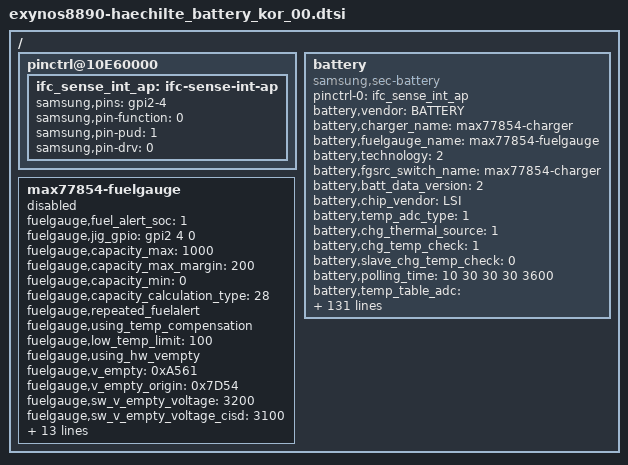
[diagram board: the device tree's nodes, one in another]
/*
 * SAMSUNG UNIVERSAL5433 board device tree source
 *
 * Copyright (c) 2013 Samsung Electronics Co., Ltd.
 *		http://www.samsung.com
 *
 * This program is free software; you can redistribute it and/or modify
 * it under the terms of the GNU General Public License version 2 as
 * published by the Free Software Foundation.
*/

/ {
	pinctrl@10E60000 {

		ifc_sense_int_ap: ifc-sense-int-ap {
			samsung,pins = "gpi2-4";
			samsung,pin-function = <0>;
			samsung,pin-pud = <1>;
			samsung,pin-drv = <0>;
		};
	};
	battery {
		status = "okay";
		compatible = "samsung,sec-battery";

		pinctrl-names = "default";
		pinctrl-0 = <&ifc_sense_int_ap>;
		/* battery,irq_gpio = <&gpa1 6 0>; */

		battery,vendor = "BATTERY";
		battery,charger_name = "max77854-charger";
		battery,fuelgauge_name = "max77854-fuelgauge";
		battery,technology = <2>; /* POWER_SUPPLY_TECHNOLOGY_LION */
		battery,fgsrc_switch_name = "max77854-charger"; /* Fuelgauge voltage source */

		battery,batt_data_version = <2>;

		battery,chip_vendor = "LSI";
		battery,temp_adc_type = <1>; /* SEC_BATTERY_ADC_TYPE_AP */

		battery,chg_thermal_source = <1>;
		battery,chg_temp_check = <1>;
		battery,slave_chg_temp_check = <0>;

		battery,polling_time = <10 30 30 30 3600>;

		battery,temp_table_adc = <325 370 425 572 640 784 910 1058 1235 1407 1600 1835 2282 2767 2970 3160 3322 3464 3688>;
		battery,temp_table_data = <900 850 800 700 650 600 550 500 450 400 350 300 200 100 50 0 (-50) (-100) (-200)>;

		battery,chg_temp_table_adc = <307 351 405 511 647 758 885 1031 1208 1363 1549 1792 2224 2738 2941 3135 3299 3455 3672>;
		battery,chg_temp_table_data = <900 850 800 700 650 600 550 500 450 400 350 300 200 100 50 0 (-50) (-100) (-200)>;

		battery,input_current_limit = <1800 450 450 1800 500 900 1000 460 1000 450 900 900 900 1900 1800 450 450 400 700 1300 300 1000 1500 450 1675 1800 1000 1675 80 1800 1675 1400 1000 1000 600 900 900 900 1675 1800>;
		battery,fast_charging_current = <2100 450 450 2100 800 1200 1000 460 1200 450 2100 2100 2100 1600 2100 450 450 400 700 1300 300 1000 1500 450 2800 2800 1000 2800 80 1800 1000 1400 450 1000 2100 2100 2100 2100 2800 2250>;
		battery,full_check_current_1st = <450 0 0 450 450 450 450 450 450 0 450 450 450 450 450 0 0 450 450 450 450 450 450 0 450 450 450 450 0 450 450 450 0 450 450 450 450 450 450 450>;
		battery,full_check_current_2nd = <250 0 0 250 250 250 250 250 250 0 250 250 250 250 250 0 0 250 250 250 250 250 250 0 250 250 250 250 0 250 250 250 0 250 250 250 250 250 250 250>;

		battery,wireless_cc_cv = <85>;
		battery,inbat_voltage = <1>;
		battery,inbat_voltage_table_adc = <3120 3101 3061 3038 3001 2956 2920 2887 2856 2814
						2793 2754 2720 2677 2641 2613 2572 2531 2502 2467 2436>;
		battery,inbat_voltage_table_data = <438 435 430 425 420 415 410 405 400 395
						390 385 380 375 370 365 360 355 350 345 340>;

		battery,adc_check_count = <5>;

		battery,cable_check_type = <4>; /* SEC_BATTERY_CABLE_CHECK_PSY */
		battery,cable_source_type = <1>; /* SEC_BATTERY_CABLE_SOURCE_EXTERNAL */
		battery,polling_type = <1>; /* SEC_BATTERY_MONITOR_ALARM */
		battery,monitor_initial_count = <0>;

		battery,battery_check_type = <5>; /* SEC_BATTERY_CHECK_CHARGER */
		battery,check_count = <0>;
		battery,check_adc_max = <1440>;
		battery,check_adc_min = <0>;

		battery,ovp_uvlo_check_type = <3>; /* SEC_BATTERY_OVP_UVLO_CHGPOLLING */

		battery,thermal_source = <2>; /* SEC_BATTERY_THERMAL_SOURCE_ADC */

		battery,temp_check_type = <2>; /* SEC_BATTERY_TEMP_CHECK_TEMP */
		battery,temp_check_count = <1>;
		battery,temp_highlimit_threshold_event = <800>;
		battery,temp_highlimit_recovery_event = <750>;
		battery,temp_high_threshold_event = <500>;
		battery,temp_high_recovery_event = <450>;
		battery,temp_low_threshold_event = <0>;
		battery,temp_low_recovery_event = <50>;
		battery,temp_highlimit_threshold_normal = <800>;
		battery,temp_highlimit_recovery_normal = <750>;
		battery,temp_high_threshold_normal = <500>;
		battery,temp_high_recovery_normal = <450>;
		battery,temp_low_threshold_normal = <0>;
		battery,temp_low_recovery_normal = <50>;
		battery,temp_highlimit_threshold_lpm = <800>;
		battery,temp_highlimit_recovery_lpm = <750>;
		battery,temp_high_threshold_lpm = <500>;
		battery,temp_high_recovery_lpm = <450>;
		battery,temp_low_threshold_lpm = <0>;
		battery,temp_low_recovery_lpm = <50>;
		battery,full_check_type = <7>; /* SEC_BATTERY_FULLCHARGED_CHGPSY */
		battery,full_check_type_2nd = <7>; /* SEC_BATTERY_FULLCHARGED_CHGPSY */
		battery,full_check_count = <1>;
		battery,chg_gpio_full_check = <0>;
		battery,chg_polarity_full_check = <1>;

		battery,chg_high_temp_1st = <515>;
		battery,chg_high_temp_2nd = <515>;
		battery,chg_high_temp_recovery = <500>;
		battery,chg_charging_limit_current = <1033>;
		battery,chg_charging_limit_current_2nd = <1033>;

		battery,sleep_mode_limit_current = <500>;
		battery,wc_full_input_limit_current = <100>;
		battery,wc_cv_current = <820>;

		battery,mix_temp_check = <1>;
		battery,mix_high_tbat = <400>;
		battery,mix_high_tchg = <500>;
		battery,mix_high_tbat_recov = <370>;
		battery,mix_input_limit_current = <100>;
		battery,mix_high_tbat_hv = <420>;
		battery,mix_high_tchg_hv = <500>;
		battery,mix_high_tbat_recov_hv = <390>;
		battery,mix_input_limit_current_hv = <100>;

		/* SEC_BATTERY_FULL_CONDITION_SOC |
		   SEC_BATTERY_FULL_CONDITION_NOTIMEFULL |
		   SEC_BATTERY_FULL_CONDITION_VCELL */
		battery,full_condition_type = <13>;
		battery,full_condition_soc = <93>;
		battery,full_condition_vcell = <4125>;

		battery,recharge_check_count = <2>;
		battery,recharge_condition_type = <4>; /* SEC_BATTERY_RECHARGE_CONDITION_VCELL */
		battery,recharge_condition_soc = <98>;
		battery,recharge_condition_vcell = <4125>;

		battery,charging_total_time = <21600>;
		battery,recharging_total_time = <5400>;
		battery,charging_reset_time = <0>;
		battery,hv_charging_total_time = <10800>;
		battery,normal_charging_total_time = <18000>;
		battery,usb_charging_total_time = <36000>;

		battery,chg_float_voltage = <42250>;

		battery,swelling_high_temp_block = <410>;
		battery,swelling_high_temp_recov = <360>;
		battery,swelling_low_temp_block = <100>;
		battery,swelling_low_temp_recov = <150>;

		battery,swelling_low_temp_current = <1050>;	/* 0.3C */
		battery,swelling_low_temp_topoff = <250>;	/* 0.05C */
		battery,swelling_high_temp_current = <1600>;	/* 0.45C */
		battery,swelling_high_temp_topoff = <250>;	/* 0.05C */

		battery,swelling_drop_float_voltage = <41000>;
		battery,swelling_high_rechg_voltage = <3900>;
		battery,swelling_low_rechg_voltage = <3900>;

		battery,siop_event_check_type = <1>;
		battery,siop_call_cv_current = <330>;
		battery,siop_call_cc_current = <330>;

		battery,siop_input_limit_current = <1200>;
		battery,siop_charging_limit_current = <1000>;
		battery,siop_hv_input_limit_current = <700>;
		battery,siop_hv_charging_limit_current = <1000>;
		battery,siop_hv_12v_input_limit_current = <535>;
		battery,siop_hv_12v_charging_limit_current = <1000>;

		battery,siop_wireless_input_limit_current = <600>;
		battery,siop_wireless_charging_limit_current = <1000>;
		battery,siop_hv_wireless_input_limit_current = <600>;
		battery,siop_hv_wireless_charging_limit_current = <1000>;

		battery,ttf_hv_charge_current = <2800>;
		battery,ttf_hv_wireless_charge_current = <1500>;

		/* cycle, chg_float_voltage, recharge_condition_vcell, full_condition_vcell, full_condition_soc */
		battery,age_data = <0 43500 4300 4250 93
			200 43250 4275 4225 89
			250 43125 4262 4212 85
			300 42875 4237 4187 80
			1000 42375 4187 4137 75>;

		/* values for using CONFIG_STEP_CHARGING */
		battery,step_charging_type = <0>;
		battery,step_charging_charge_power = <20000>;
		battery,step_charging_condtion = <4100 4400>;
		battery,step_charging_current = <2800 2800>;
		/* values for not using CONFIG_STEP_CHARGING */
		battery,base_charge_power = <20000>;
		battery,max_charging_current = <2800>;

		battery,max_input_voltage = <12000>; /* mV */
		battery,max_input_current = <3000>;  /* mA */

		io-channels = <&exynos_adc 1>, <&exynos_adc 3>, <&exynos_adc 6>;
		io-channel-names = "adc-temp", "adc-chg-temp", "adc-in-bat";
		#io-channel-cells = <3>;
		io-channel-ranges;
	};

	max77854-fuelgauge {
		status = "disable";

		fuelgauge,fuel_alert_soc = <1>;
		fuelgauge,jig_gpio = <&gpi2 4 0>;
		fuelgauge,capacity_max = <1000>;
		fuelgauge,capacity_max_margin = <200>;
		fuelgauge,capacity_min = <0>;
		fuelgauge,capacity_calculation_type = <28>;
		fuelgauge,repeated_fuelalert;
		fuelgauge,using_temp_compensation;
		fuelgauge,low_temp_limit = <100>;
		fuelgauge,using_hw_vempty;
		fuelgauge,v_empty = <0xA561>; /* Empty: 3260mV, Recover: 3480mV */
		fuelgauge,v_empty_origin = <0x7D54>; /* Empty: 2500mV, Recover: 3360mV */
		fuelgauge,sw_v_empty_voltage = <3200>;
		fuelgauge,sw_v_empty_voltage_cisd = <3100>;
		fuelgauge,sw_v_empty_recover_voltage = <3480>;
		fuelgauge,qrtable20 = <0x0901>;
		fuelgauge,qrtable30 = <0x0803>;
		fuelgauge,fg_resistor = <1>;
		fuelgauge,rcomp0 = <0x6B>;
		fuelgauge,rcomp_charging = <0x6B>;
		fuelgauge,is_using_model_data;
		fuelgauge,type_str = "SDI";
		fuelgauge,capacity = <0x1EED>;
		/*fuelgauge,auto_discharge_en;*/
		fuelgauge,discharge_temp_threshold = <600>;
		fuelgauge,discharge_volt_threshold = <4540>;
		fuelgauge,cv_data = <2493  832  1437
			2354  840  1405
			2225  846  1373
			2202  848  1367
			2179  849  1360
			2162  850  1355
			2150  851  1351
			2064  855  1327
			1973  860  1301
			1960  861  1297
			1908  864  1281
			1813  869  1249
			1727  874  1219
			1635  879  1186
			1605  881  1175
			1575  883  1163
			1563  883  1158
			1482  888  1126
			1441  890  1109
			1388  893  1086
			1365  895  1075
			1351  895  1068
			1289  899  1040
			1267  900  1030
			1242  902  1017
			1227  903  1009
			1200  904  994 
			1138  908  963 
			1087  912  933 
			1085  912  931 
			1074  913  925 
			1018  916  891 
			988   917  874 
			957   920  852 
			939   920  840 
			924   922  828 
			871   924  796 
			834   927  764 
			818   928  752 
			807   928  744 
			800   929  738 
			795   929  733 
			778   930  718 
			771   931  710 
			739   933  683 
			730   933  675 
			721   934  669 
			715   934  661 
			714   934  660 
			699   935  645 
			695   936  641 
			679   936  628 
			672   937  622 
			650   938  596 
			625   940  566 
			613   941  556 
			606   941  545 
			594   942  533 
			591   943  531 
			585   944  523 
			581   945  518 
			576   946  514 
			569   947  505 
			567   948  503 
			565   948  499 
			564   948  495 
			559   949  487 
			535   954  456 
			532   955  453 
			523   956  441 
			515   958  430 
			506   960  418 
			486   964  387 
			469   967  362 
			468   967  359 
			462   968  349 
			454   970  334 
			435   973  302 
			434   974  300 
			428   975  291 
			422   976  280 
			407   979  248 
			406   979  247 
			404   979  244 
			389   982  218 
			386   983  213 
			375   985  188 
			368   986  175 
			355   989  143 
			338   992  111 
			337   993  103 
			331   994  88  
			319   996  56  
			310   998  39  
			307   998  32  
			0   1000 0>;
	};

};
